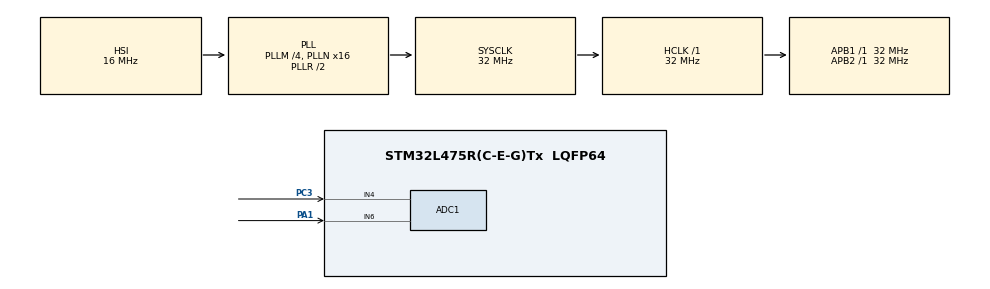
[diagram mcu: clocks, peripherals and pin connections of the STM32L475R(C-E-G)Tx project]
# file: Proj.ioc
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ADC1.Channel-0\#ChannelRegularConversion=ADC_CHANNEL_4
ADC1.Channel-1\#ChannelRegularConversion=ADC_CHANNEL_6
ADC1.ClockPrescaler=ADC_CLOCK_ASYNC_DIV2
ADC1.EOCSelection=ADC_EOC_SEQ_CONV
ADC1.NbrOfConversion=2
ADC1.NbrOfConversionFlag=1
ADC1.OffsetNumber-0\#ChannelRegularConversion=ADC_OFFSET_NONE
ADC1.OffsetNumber-1\#ChannelRegularConversion=ADC_OFFSET_NONE
ADC1.Rank-0\#ChannelRegularConversion=1
ADC1.Rank-1\#ChannelRegularConversion=2
ADC1.SamplingTime-0\#ChannelRegularConversion=ADC_SAMPLETIME_6CYCLES_5
ADC1.SamplingTime-1\#ChannelRegularConversion=ADC_SAMPLETIME_6CYCLES_5
ADC1.master=1
Mcu.Family=STM32L4
Mcu.Name=STM32L475R(C-E-G)Tx
Mcu.Package=LQFP64
NVIC.ADC1_2_IRQn=true\:0\:0\:false\:false\:true\:true\:true
NVIC.PriorityGroup=NVIC_PRIORITYGROUP_4
PA1.Signal=ADCx_IN6
PC3.Signal=ADCx_IN4
ProjectManager.HeapSize=0x200
ProjectManager.StackSize=0x400
ProjectManager.TargetToolchain=STM32CubeIDE
RCC.ADCCLockSelection=RCC_ADCCLKSOURCE_PLLSAI2
RCC.ADCFreq_Value=16000000
RCC.AHBFreq_Value=32000000
RCC.APB1Freq_Value=32000000
RCC.APB1TimFreq_Value=32000000
RCC.APB2Freq_Value=32000000
RCC.APB2TimFreq_Value=32000000
RCC.CortexFreq_Value=32000000
RCC.HCLKFreq_Value=32000000
RCC.HSE_VALUE=8000000
RCC.HSI_VALUE=16000000
RCC.LSE_VALUE=32768
RCC.MSI_VALUE=4000000
RCC.PLLM=4
RCC.PLLN=16
RCC.PLLSAI1N=30
RCC.PLLSAI2N=16
RCC.PLLSAI2R=RCC_PLLR_DIV4
RCC.PLLSourceVirtual=RCC_PLLSOURCE_HSI
RCC.SYSCLKFreq_VALUE=32000000
RCC.SYSCLKSource=RCC_SYSCLKSOURCE_PLLCLK
RCC.USBFreq_Value=60000000
RCC.VCOOutputFreq_Value=64000000
SH.ADCx_IN4.0=ADC1_IN4,IN4-Single-Ended
SH.ADCx_IN6.0=ADC1_IN6,IN6-Single-Ended
board=custom

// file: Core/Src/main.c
/* USER CODE BEGIN Header */
/**
  ******************************************************************************
  * @file           : main.c
  * @brief          : Main program body
  ******************************************************************************
  * @attention
  *
  * <h2><center>&copy; Copyright (c) 2022 STMicroelectronics.
  * All rights reserved.</center></h2>
  *
  * This software component is licensed by ST under BSD 3-Clause license,
  * the "License"; You may not use this file except in compliance with the
  * License. You may obtain a copy of the License at:
  *                        opensource.org/licenses/BSD-3-Clause
  *
  ******************************************************************************
  */
/* USER CODE END Header */
#include "main.h"

ADC_HandleTypeDef hadc1;

void SystemClock_Config(void);
static void MX_GPIO_Init(void);
static void MX_ADC1_Init(void);

int main(void)
{
  /* USER CODE BEGIN 1 */
//	HAL_ADC_Start(&hadc1);
//	HAL_ADC_Start(&hadc1);
	HAL_ADC_Start_IT(&hadc1);
  /* USER CODE END 1 */

  /* MCU Configuration--------------------------------------------------------*/

  /* Reset of all peripherals, Initializes the Flash interface and the Systick. */
  HAL_Init();

  /* Configure the system clock */
  SystemClock_Config();

  /* Initialize all configured peripherals */
  MX_GPIO_Init();
  MX_ADC1_Init();

  /* Infinite loop */
  while (1)
  {

  }
}

void SystemClock_Config(void)
{
  RCC_OscInitTypeDef RCC_OscInitStruct = {0};
  RCC_ClkInitTypeDef RCC_ClkInitStruct = {0};

  /** Configure the main internal regulator output voltage
  */
  if (HAL_PWREx_ControlVoltageScaling(PWR_REGULATOR_VOLTAGE_SCALE1) != HAL_OK)
  {
    Error_Handler();
  }
  /** Initializes the RCC Oscillators according to the specified parameters
  * in the RCC_OscInitTypeDef structure.
  */
  RCC_OscInitStruct.OscillatorType = RCC_OSCILLATORTYPE_HSI;
  RCC_OscInitStruct.HSIState = RCC_HSI_ON;
  RCC_OscInitStruct.HSICalibrationValue = RCC_HSICALIBRATION_DEFAULT;
  RCC_OscInitStruct.PLL.PLLState = RCC_PLL_ON;
  RCC_OscInitStruct.PLL.PLLSource = RCC_PLLSOURCE_HSI;
  RCC_OscInitStruct.PLL.PLLM = 4;
  RCC_OscInitStruct.PLL.PLLN = 16;
  RCC_OscInitStruct.PLL.PLLP = RCC_PLLP_DIV7;
  RCC_OscInitStruct.PLL.PLLQ = RCC_PLLQ_DIV2;
  RCC_OscInitStruct.PLL.PLLR = RCC_PLLR_DIV2;
  if (HAL_RCC_OscConfig(&RCC_OscInitStruct) != HAL_OK)
  {
    Error_Handler();
  }
  /** Initializes the CPU, AHB and APB buses clocks
  */
  RCC_ClkInitStruct.ClockType = RCC_CLOCKTYPE_HCLK|RCC_CLOCKTYPE_SYSCLK
                              |RCC_CLOCKTYPE_PCLK1|RCC_CLOCKTYPE_PCLK2;
  RCC_ClkInitStruct.SYSCLKSource = RCC_SYSCLKSOURCE_PLLCLK;
  RCC_ClkInitStruct.AHBCLKDivider = RCC_SYSCLK_DIV1;
  RCC_ClkInitStruct.APB1CLKDivider = RCC_HCLK_DIV1;
  RCC_ClkInitStruct.APB2CLKDivider = RCC_HCLK_DIV1;

  if (HAL_RCC_ClockConfig(&RCC_ClkInitStruct, FLASH_LATENCY_1) != HAL_OK)
  {
    Error_Handler();
  }
}

static void MX_ADC1_Init(void)
{

  ADC_MultiModeTypeDef multimode = {0};
  ADC_ChannelConfTypeDef sConfig = {0};

  /** Common config
  */
  hadc1.Instance = ADC1;
  hadc1.Init.ClockPrescaler = ADC_CLOCK_ASYNC_DIV2;
  hadc1.Init.Resolution = ADC_RESOLUTION_12B;
  hadc1.Init.DataAlign = ADC_DATAALIGN_RIGHT;
  hadc1.Init.ScanConvMode = ADC_SCAN_ENABLE;
  hadc1.Init.EOCSelection = ADC_EOC_SEQ_CONV;
  hadc1.Init.LowPowerAutoWait = DISABLE;
  hadc1.Init.ContinuousConvMode = DISABLE;
  hadc1.Init.NbrOfConversion = 2;
  hadc1.Init.DiscontinuousConvMode = DISABLE;
  hadc1.Init.ExternalTrigConv = ADC_SOFTWARE_START;
  hadc1.Init.ExternalTrigConvEdge = ADC_EXTERNALTRIGCONVEDGE_NONE;
  hadc1.Init.DMAContinuousRequests = DISABLE;
  hadc1.Init.Overrun = ADC_OVR_DATA_PRESERVED;
  hadc1.Init.OversamplingMode = DISABLE;
  if (HAL_ADC_Init(&hadc1) != HAL_OK)
  {
    Error_Handler();
  }
  /** Configure the ADC multi-mode
  */
  multimode.Mode = ADC_MODE_INDEPENDENT;
  if (HAL_ADCEx_MultiModeConfigChannel(&hadc1, &multimode) != HAL_OK)
  {
    Error_Handler();
  }
  /** Configure Regular Channel
  */
  sConfig.Channel = ADC_CHANNEL_4;
  sConfig.Rank = ADC_REGULAR_RANK_1;
  sConfig.SamplingTime = ADC_SAMPLETIME_6CYCLES_5;
  sConfig.SingleDiff = ADC_SINGLE_ENDED;
  sConfig.OffsetNumber = ADC_OFFSET_NONE;
  sConfig.Offset = 0;
  if (HAL_ADC_ConfigChannel(&hadc1, &sConfig) != HAL_OK)
  {
    Error_Handler();
  }
  /** Configure Regular Channel
  */
  sConfig.Channel = ADC_CHANNEL_6;
  sConfig.Rank = ADC_REGULAR_RANK_2;
  if (HAL_ADC_ConfigChannel(&hadc1, &sConfig) != HAL_OK)
  {
    Error_Handler();
  }

}

static void MX_GPIO_Init(void)
{

  /* GPIO Ports Clock Enable */
  __HAL_RCC_GPIOC_CLK_ENABLE();
  __HAL_RCC_GPIOA_CLK_ENABLE();

}

/* USER CODE BEGIN 4 */
void HAL_ADC_ConvCpltCallback(ADC_HandleTypeDef*  hadc)
{
	asm("nop");
	HAL_ADC_Start_IT(hadc);
}
/* USER CODE END 4 */

void Error_Handler(void)
{
  __disable_irq();
  while (1)
  {
  }
}

/************************ (C) COPYRIGHT STMicroelectronics *****END OF FILE****/
